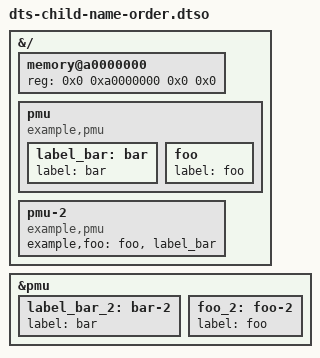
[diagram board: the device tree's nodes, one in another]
// SPDX-License-Identifier: GPL-2.0-only OR BSD-2-Clause
/dts-v1/;
/plugin/;

&{/} {
	#address-cells = <1>;
	#size-cells = <1>;

	memory@a0000000 {
		device_type = "memory";
		reg = <0x0 0xa0000000 0x0 0x0>;
	};

	pmu {
		compatible = "example,pmu";

		/* Include labels to be sure they do not affect sorting */
		label_bar: bar {
			label = "bar";
		};

		foo: foo {
			label = "foo";
		};
	};

	pmu-2 {
		compatible = "example,pmu";

		/* Just reference labels to avoid strict warnings */
		example,foo = <&foo>, <&label_bar>;
	};
};

&pmu {
	/* Include labels to be sure they do not affect sorting */
	label_bar_2: bar-2 {
		label = "bar";
	};

	foo_2: foo-2 {
		label = "foo";
	};
}
